# STM32H5E4xx register map
File version: 1.0
Registers are 32-bit, read-write, reset 0x0 unless marked. A register's access mark holds for its fields unless they carry their own. Offsets are from the block's base; [hi:lo] are bit positions; {n}, {i} and the like mark numbered series.

## PKA
Base 0x420C2000
Same registers: PKA_S 0x520C2000
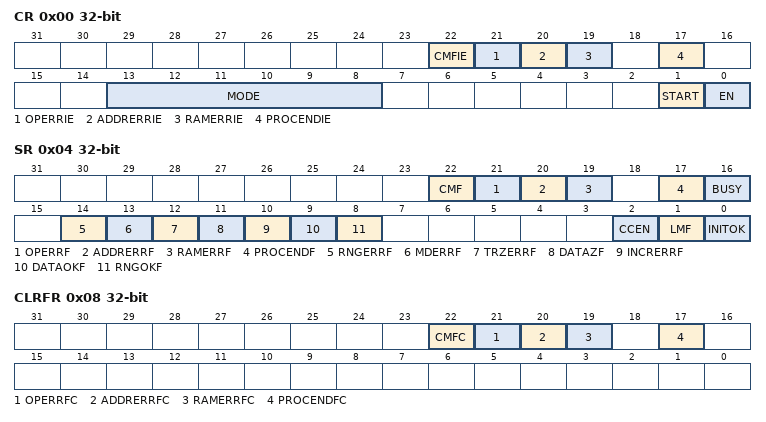
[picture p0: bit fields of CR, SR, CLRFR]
0x00 CR — PKA control register
  [22] CMFIE
  [21] OPERRIE — Operation Error interrupt enable
  [20] ADDRERRIE — Address error interrupt enable
  [19] RAMERRIE — RAM error interrupt enable
  [17] PROCENDIE — End of operation interrupt enable
  [13:8] MODE — MODE[5:0] PKA operation code
  [1] START — Start operation
  [0] EN — PKA enable
0x04 SR — PKA status register
  [22] CMF — Chaining mode flag
  [21] OPERRF — PKA operation Error flag
  [20] ADDRERRF — Address error flag
  [19] RAMERRF — PKA RAM error flag
  [17] PROCENDF — PKA end of operation flag
  [16] BUSY — PKA operation is in progress
  [14] RNGERRF — PKA RNG error flag
  [13] MDERRF — PKA Mode error flag
  [12] TRZERRF — PKA Trailing zeros error flag
  [11] DATAZF — PKA Data zeroed error flag
  [10] INCRERRF — PKA Increment error flag
  [9] DATAOKF — PKA Data OK flag
  [8] RNGOKF — PKA RNG OK flag
  [2] CCEN — PKA Coupling and chaining mode enable
  [1] LMF — PKA Limited mode flag
  [0] INITOK — PKA initialisation flag
0x08 CLRFR — PKA clear flag register
  [22] CMFC — Clear chaining mode flag
  [21] OPERRFC — Clear PKA operation Error flag
  [20] ADDRERRFC — Clear address error flag
  [19] RAMERRFC — Clear PKA RAM error flag
  [17] PROCENDFC — Clear PKA end of operation flag
{0x400+4i} RAM[{i}] (i=0..1333)

## SBS — System configuration, Boot and Security
Base 0x44000400
Same registers: SBS_S 0x54000400
0x10 HDPLCR — SBS HDPL Control Register
  [7:0] INCR_HDPL — Increment HDPL value
0x14 HDPLSR — SBS HDPL Status Register
  [7:0] HDPL — HDPL value
0x18 NEXTHDPLCR — NEXT HDPL Control Register
  [1:0] NEXTHDPL — NEXTHDPL value
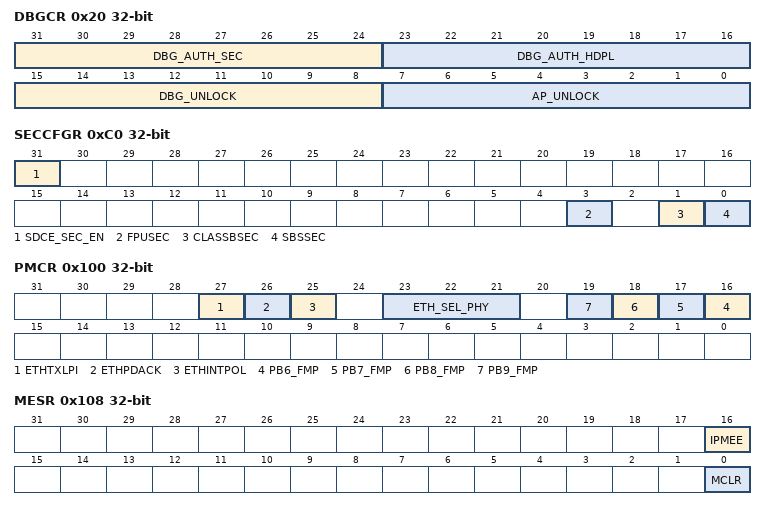
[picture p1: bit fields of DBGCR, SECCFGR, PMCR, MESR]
0x20 DBGCR — SBS Debug Control Register
  [31:24] DBG_AUTH_SEC — Open the non-secured and secured debugs
  [23:16] DBG_AUTH_HDPL — HDPL value when the debug should be effectively opened
  [15:8] DBG_UNLOCK — Open the debug when DBG_AUTH_HDPL is reached
  [7:0] AP_UNLOCK — Open the Access Port
0x24 DBGLOCKR — SBS Debug Lock Register
  [7:0] DBGCFG_LOCK — SBS_DBGLOCKR_DBGCFG_LOCK value
0x34 RSSCMDR — SBS RSS Command Register
  [15:0] RSSCMD — command to be executed by the RSS
0xA0 EPOCHSELCR — EPOCH Selection Register
  [1:0] EPOCH_SEL — Select EPOCH sent to SAES IP to encrypt/decrypt keys
0xC0 SECCFGR — SBS Security Mode Configuration
  [31] SDCE_SEC_EN — SMPS SBS security enable
  [3] FPUSEC — FPU SBS security enable
  [1] CLASSBSEC — ClassB SBS security enable
  [0] SBSSEC — SBS clock control security enable
0x100 PMCR — SBS Product Mode & Config Register
  [27] ETHTXLPI — ETH TxLPI status
  [26] ETHPDACK — ETH power-down acknowledge
  [25] ETHINTPOL — ETH external PHY interrupt polarity configuration
  [23:21] ETH_SEL_PHY — Ethernet PHY Interface Selection
    0=MII (Select the Media Independent Interface (MII) or GMII); 4=RMII (Select the Reduced Media Independent Interface (RMII))
  [n+10] PB{n}_FMP (n=6..9) — Fast-mode Plus command on PB({n})
0x104 FPUIMR — SBS FPU Interrupt Mask Register
  [5:0] FPU_IE — All FPU interrupts enable
0x108 MESR — SBS Memory Erase Status Register
  [16] IPMEE — Status of End of Erase for ICache and PKA RAMs
  [0] MCLR — Status of Erase after Reset
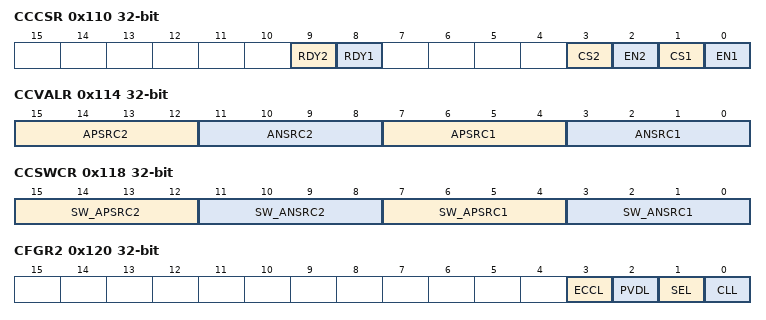
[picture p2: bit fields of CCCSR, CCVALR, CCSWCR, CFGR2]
0x110 CCCSR — SBS Compensation Cell Control & Status Register
  [9] RDY2 — VDDIO compensation cell ready flag
  [8] RDY1 — VDD compensation cell ready flag
  [3] CS2 — Code selection for VDDIO power rail
  [2] EN2 — Enable compensation cell for VDDIO power rail
  [1] CS1 — Code selection for VDD power rail
  [0] EN1 — Enable compensation cell for VDD power rail
0x114 CCVALR — SBS Compensation Cell Value Register
  [15:12] APSRC2 — PMOS compensation value
  [11:8] ANSRC2 — NMOS compensation value
  [7:4] APSRC1 — PMOS compensation value
  [3:0] ANSRC1 — NMOS compensation value
0x118 CCSWCR — SBS Compensation Cell for I/Os sw code Register
  [15:12] SW_APSRC2 — PMOS compensation code for VDDIO Power Rail
  [11:8] SW_ANSRC2 — NMOS compensation code for VDDIO Power Rail
  [7:4] SW_APSRC1 — PMOS compensation code for VDD Power Rail
  [3:0] SW_ANSRC1 — NMOS compensation code for VDD Power Rail
0x120 CFGR2 — SBS Class B Register
  [3] ECCL — Flash ECC Lock
  [2] PVDL — PVD Lock
  [1] SEL — SRAM ECC Lock
  [0] CLL — Core Lockup Lock
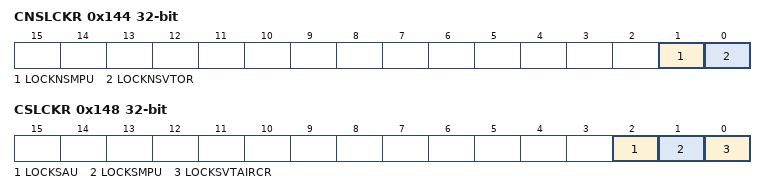
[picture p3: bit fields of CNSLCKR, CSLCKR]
0x144 CNSLCKR — SBS CPU Non-secure Lock Register
  [1] LOCKNSMPU — Disable Non-Secure MPU registers writes by SW or debug agent
  [0] LOCKNSVTOR — Disable VTOR_NS register writes by SW or debug agent
0x148 CSLCKR — SBS CPU Secure Lock Register
  [2] LOCKSAU — Disable changes to SAU registers
  [1] LOCKSMPU — Disable changes to the secure MPU registers writes by SW or debug agent
  [0] LOCKSVTAIRCR — Disable changes to the secure vector table address, handling of system faults
0x14C ECCNMIR — SBS FLITF ECC NMI MASK Register
  [0] ECCNMI_MASK_EN — Disable NMI in case of double ECC error in flash interface
